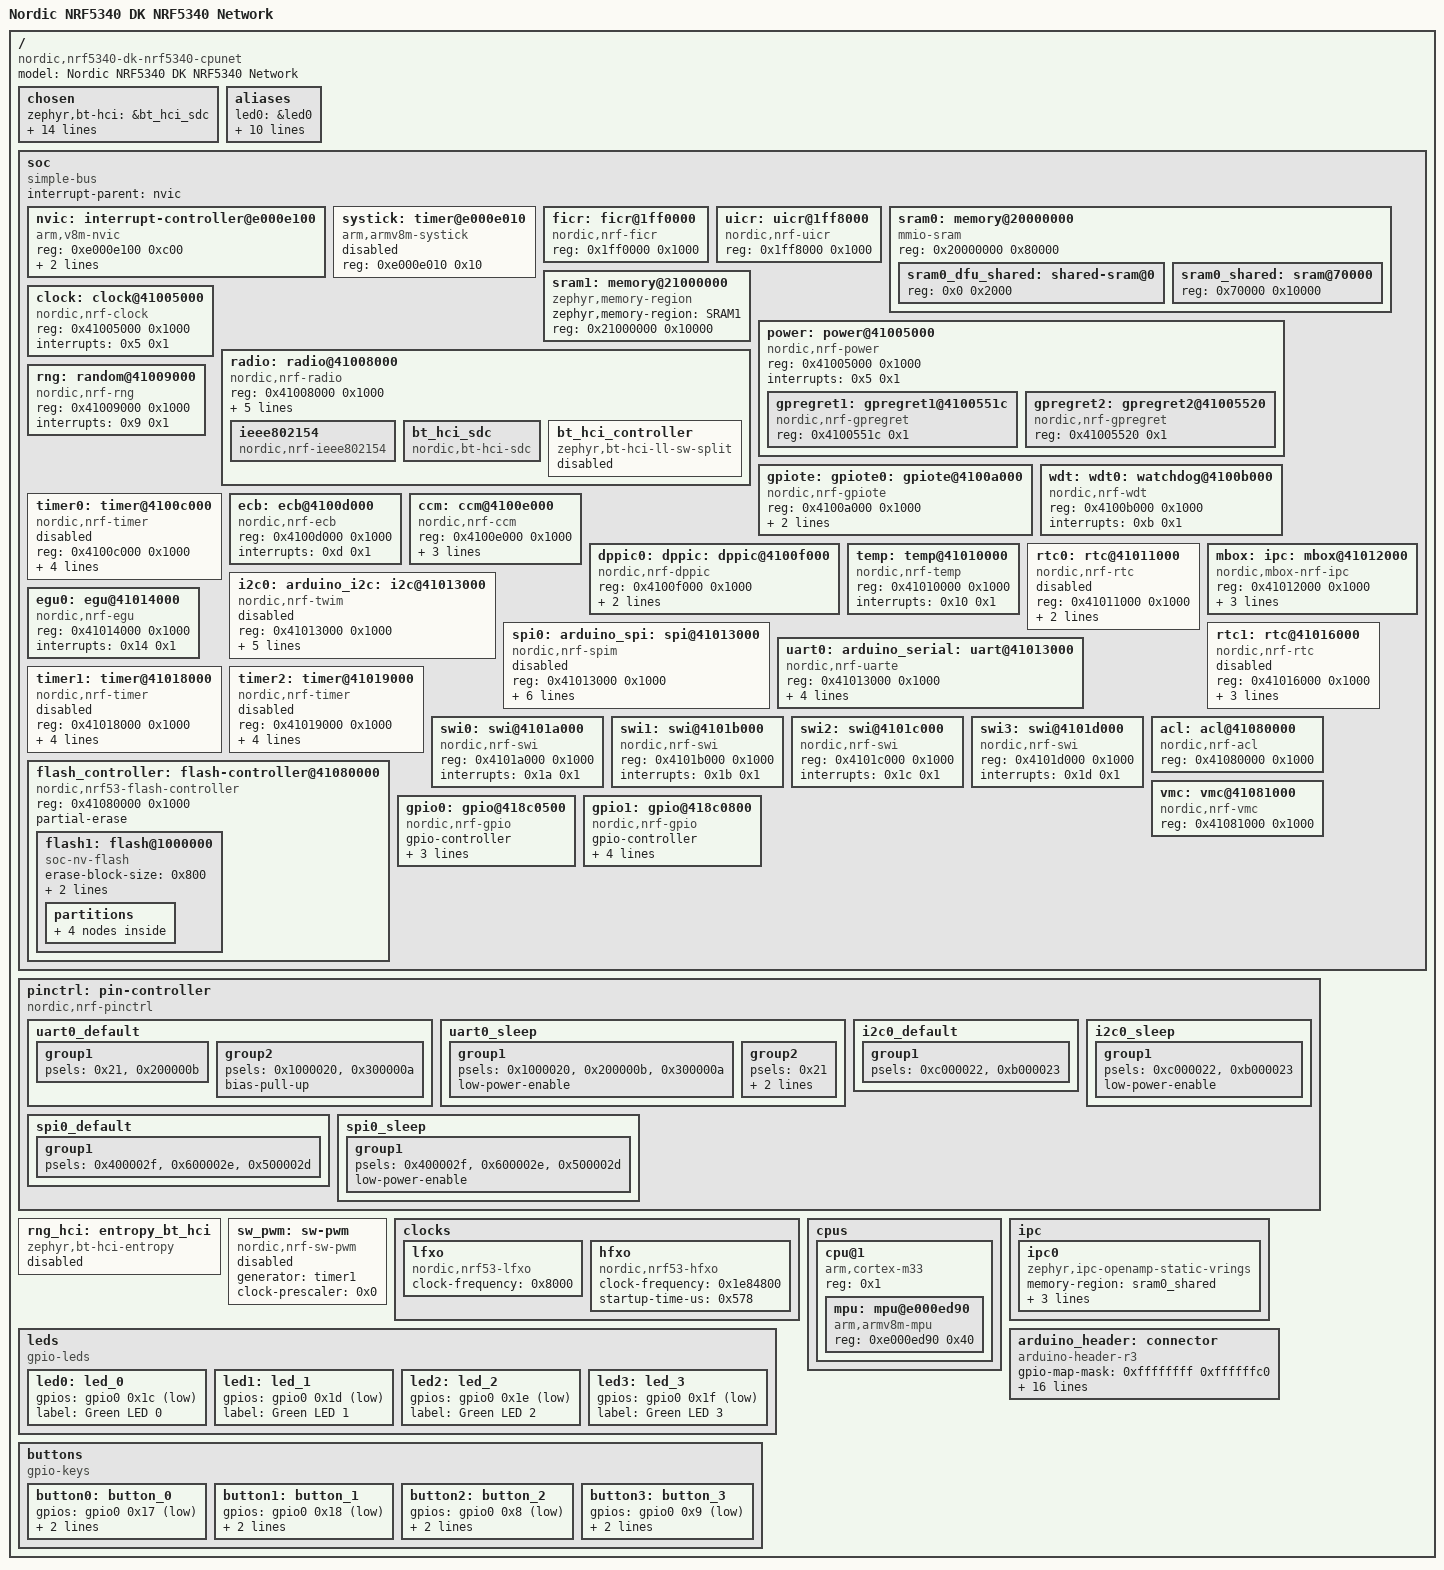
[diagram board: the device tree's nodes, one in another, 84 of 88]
/dts-v1/;

/* node '/' defined in zephyr/dts/common/skeleton.dtsi:9 */
/ {
	#address-cells = < 0x1 >;                        /* in zephyr/dts/common/skeleton.dtsi:10 */
	#size-cells = < 0x1 >;                           /* in zephyr/dts/common/skeleton.dtsi:11 */
	model = "Nordic NRF5340 DK NRF5340 Network";     /* in zephyr/boards/nordic/nrf5340dk/nrf5340dk_nrf5340_cpunet.dts:14 */
	compatible = "nordic,nrf5340-dk-nrf5340-cpunet"; /* in zephyr/boards/nordic/nrf5340dk/nrf5340dk_nrf5340_cpunet.dts:15 */

	/* node '/chosen' defined in zephyr/dts/common/skeleton.dtsi:13 */
	chosen {
		zephyr,bt-hci = &bt_hci_sdc;                 /* in zephyr/dts/arm/nordic/nrf5340_cpunet.dtsi:13 */
		zephyr,entropy = &rng;                       /* in zephyr/dts/arm/nordic/nrf5340_cpunet.dtsi:14 */
		zephyr,flash-controller = &flash_controller; /* in zephyr/dts/arm/nordic/nrf5340_cpunet.dtsi:15 */
		zephyr,console = &uart0;                     /* in zephyr/boards/nordic/nrf5340dk/nrf5340dk_nrf5340_cpunet.dts:18 */
		zephyr,shell-uart = &uart0;                  /* in zephyr/boards/nordic/nrf5340dk/nrf5340dk_nrf5340_cpunet.dts:19 */
		zephyr,uart-mcumgr = &uart0;                 /* in zephyr/boards/nordic/nrf5340dk/nrf5340dk_nrf5340_cpunet.dts:20 */
		zephyr,bt-mon-uart = &uart0;                 /* in zephyr/boards/nordic/nrf5340dk/nrf5340dk_nrf5340_cpunet.dts:21 */
		zephyr,bt-c2h-uart = &uart0;                 /* in zephyr/boards/nordic/nrf5340dk/nrf5340dk_nrf5340_cpunet.dts:22 */
		zephyr,bt-hci-ipc = &ipc0;                   /* in zephyr/boards/nordic/nrf5340dk/nrf5340dk_nrf5340_cpunet.dts:23 */
		nordic,802154-spinel-ipc = &ipc0;            /* in zephyr/boards/nordic/nrf5340dk/nrf5340dk_nrf5340_cpunet.dts:24 */
		zephyr,sram = &sram1;                        /* in zephyr/boards/nordic/nrf5340dk/nrf5340dk_nrf5340_cpunet.dts:25 */
		zephyr,flash = &flash1;                      /* in zephyr/boards/nordic/nrf5340dk/nrf5340dk_nrf5340_cpunet.dts:26 */
		zephyr,code-partition = &slot0_partition;    /* in zephyr/boards/nordic/nrf5340dk/nrf5340dk_nrf5340_cpunet.dts:27 */
		zephyr,ieee802154 = &ieee802154;             /* in zephyr/boards/nordic/nrf5340dk/nrf5340dk_nrf5340_cpunet.dts:28 */
		zephyr,ipc_shm = &sram0_shared;              /* in zephyr/dts/vendor/nordic/nrf5340_shared_sram_partition.dtsi:22 */
	};

	/* node '/aliases' defined in zephyr/dts/common/skeleton.dtsi:15 */
	aliases {
		led0 = &led0;               /* in zephyr/boards/nordic/nrf5340dk/nrf5340dk_common.dtsi:93 */
		led1 = &led1;               /* in zephyr/boards/nordic/nrf5340dk/nrf5340dk_common.dtsi:94 */
		led2 = &led2;               /* in zephyr/boards/nordic/nrf5340dk/nrf5340dk_common.dtsi:95 */
		led3 = &led3;               /* in zephyr/boards/nordic/nrf5340dk/nrf5340dk_common.dtsi:96 */
		sw0 = &button0;             /* in zephyr/boards/nordic/nrf5340dk/nrf5340dk_common.dtsi:97 */
		sw1 = &button1;             /* in zephyr/boards/nordic/nrf5340dk/nrf5340dk_common.dtsi:98 */
		sw2 = &button2;             /* in zephyr/boards/nordic/nrf5340dk/nrf5340dk_common.dtsi:99 */
		sw3 = &button3;             /* in zephyr/boards/nordic/nrf5340dk/nrf5340dk_common.dtsi:100 */
		mcuboot-button0 = &button0; /* in zephyr/boards/nordic/nrf5340dk/nrf5340dk_common.dtsi:101 */
		mcuboot-led0 = &led0;       /* in zephyr/boards/nordic/nrf5340dk/nrf5340dk_common.dtsi:102 */
		watchdog0 = &wdt0;          /* in zephyr/boards/nordic/nrf5340dk/nrf5340dk_nrf5340_cpunet.dts:33 */
	};

	/* node '/soc' defined in zephyr/dts/arm/armv8-m.dtsi:6 */
	soc {
		#address-cells = < 0x1 >;     /* in zephyr/dts/arm/armv8-m.dtsi:7 */
		#size-cells = < 0x1 >;        /* in zephyr/dts/arm/armv8-m.dtsi:8 */
		interrupt-parent = < &nvic >; /* in zephyr/dts/arm/armv8-m.dtsi:10 */
		ranges;                       /* in zephyr/dts/arm/armv8-m.dtsi:11 */
		compatible = "simple-bus";    /* in zephyr/dts/arm/nordic/nrf5340_cpunet.dtsi:37 */

		/* node '/soc/interrupt-controller@e000e100' defined in zephyr/dts/arm/armv8-m.dtsi:13 */
		nvic: interrupt-controller@e000e100 {
			#address-cells = < 0x1 >;            /* in zephyr/dts/arm/armv8-m.dtsi:14 */
			compatible = "arm,v8m-nvic";         /* in zephyr/dts/arm/armv8-m.dtsi:15 */
			reg = < 0xe000e100 0xc00 >;          /* in zephyr/dts/arm/armv8-m.dtsi:16 */
			interrupt-controller;                /* in zephyr/dts/arm/armv8-m.dtsi:17 */
			#interrupt-cells = < 0x2 >;          /* in zephyr/dts/arm/armv8-m.dtsi:18 */
			arm,num-irq-priority-bits = < 0x3 >; /* in zephyr/dts/arm/nordic/nrf5340_cpunet.dtsi:379 */
			phandle = < 0x1 >;                   /* in zephyr/dts/arm/armv8-m.dtsi:10 */
		};

		/* node '/soc/timer@e000e010' defined in zephyr/dts/arm/armv8-m.dtsi:21 */
		systick: timer@e000e010 {
			compatible = "arm,armv8m-systick"; /* in zephyr/dts/arm/armv8-m.dtsi:22 */
			reg = < 0xe000e010 0x10 >;         /* in zephyr/dts/arm/armv8-m.dtsi:23 */
			status = "disabled";               /* in zephyr/dts/arm/nordic/nrf5340_cpunet.dtsi:384 */
		};

		/* node '/soc/ficr@1ff0000' defined in zephyr/dts/arm/nordic/nrf5340_cpunet.dtsi:39 */
		ficr: ficr@1ff0000 {
			compatible = "nordic,nrf-ficr"; /* in zephyr/dts/arm/nordic/nrf5340_cpunet.dtsi:40 */
			reg = < 0x1ff0000 0x1000 >;     /* in zephyr/dts/arm/nordic/nrf5340_cpunet.dtsi:41 */
			#nordic,ficr-cells = < 0x1 >;   /* in zephyr/dts/arm/nordic/nrf5340_cpunet.dtsi:42 */
			status = "okay";                /* in zephyr/dts/arm/nordic/nrf5340_cpunet.dtsi:43 */
		};

		/* node '/soc/uicr@1ff8000' defined in zephyr/dts/arm/nordic/nrf5340_cpunet.dtsi:46 */
		uicr: uicr@1ff8000 {
			compatible = "nordic,nrf-uicr";    /* in zephyr/dts/arm/nordic/nrf5340_cpunet.dtsi:47 */
			reg = < 0x1ff8000 0x1000 >;        /* in zephyr/dts/arm/nordic/nrf5340_cpunet.dtsi:48 */
			ranges = < 0x0 0x1ff8000 0x1000 >; /* in zephyr/dts/arm/nordic/nrf5340_cpunet.dtsi:49 */
			status = "okay";                   /* in zephyr/dts/arm/nordic/nrf5340_cpunet.dtsi:50 */
			#address-cells = < 0x1 >;          /* in zephyr/dts/arm/nordic/nrf5340_cpunet.dtsi:51 */
			#size-cells = < 0x1 >;             /* in zephyr/dts/arm/nordic/nrf5340_cpunet.dtsi:52 */
		};

		/* node '/soc/memory@20000000' defined in zephyr/dts/arm/nordic/nrf5340_cpunet.dtsi:55 */
		sram0: memory@20000000 {
			compatible = "mmio-sram";            /* in zephyr/dts/arm/nordic/nrf5340_cpunet.dtsi:56 */
			#address-cells = < 0x1 >;            /* in zephyr/dts/arm/nordic/nrf5340_cpunet.dtsi:57 */
			#size-cells = < 0x1 >;               /* in zephyr/dts/arm/nordic/nrf5340_cpunet.dtsi:58 */
			reg = < 0x20000000 0x80000 >;        /* in zephyr/dts/arm/nordic/nrf5340_cpunet_qkaa.dtsi:11 */
			ranges = < 0x0 0x20000000 0x80000 >; /* in zephyr/dts/arm/nordic/nrf5340_cpunet_qkaa.dtsi:12 */

			/* node '/soc/memory@20000000/shared-sram@0' defined in zephyr/dts/vendor/nordic/nrf5340_shared_sram_partition.dtsi:27 */
			sram0_dfu_shared: shared-sram@0 {
				reg = < 0x0 0x2000 >; /* in zephyr/dts/vendor/nordic/nrf5340_shared_sram_partition.dtsi:28 */
			};

			/* node '/soc/memory@20000000/sram@70000' defined in zephyr/dts/vendor/nordic/nrf5340_shared_sram_partition.dtsi:31 */
			sram0_shared: sram@70000 {
				reg = < 0x70000 0x10000 >; /* in zephyr/dts/vendor/nordic/nrf5340_shared_sram_partition.dtsi:33 */
				phandle = < 0xb >;         /* in zephyr/dts/arm/nordic/nrf5340_cpunet.dtsi:369 */
			};
		};

		/* node '/soc/memory@21000000' defined in zephyr/dts/arm/nordic/nrf5340_cpunet.dtsi:61 */
		sram1: memory@21000000 {
			compatible = "zephyr,memory-region",
			             "mmio-sram";            /* in zephyr/dts/arm/nordic/nrf5340_cpunet.dtsi:62 */
			zephyr,memory-region = "SRAM1";      /* in zephyr/dts/arm/nordic/nrf5340_cpunet.dtsi:63 */
			#address-cells = < 0x1 >;            /* in zephyr/dts/arm/nordic/nrf5340_cpunet.dtsi:64 */
			#size-cells = < 0x1 >;               /* in zephyr/dts/arm/nordic/nrf5340_cpunet.dtsi:65 */
			reg = < 0x21000000 0x10000 >;        /* in zephyr/dts/arm/nordic/nrf5340_cpunet_qkaa.dtsi:16 */
			ranges = < 0x0 0x21000000 0x10000 >; /* in zephyr/dts/arm/nordic/nrf5340_cpunet_qkaa.dtsi:17 */
		};

		/* node '/soc/clock@41005000' defined in zephyr/dts/arm/nordic/nrf5340_cpunet.dtsi:68 */
		clock: clock@41005000 {
			compatible = "nordic,nrf-clock"; /* in zephyr/dts/arm/nordic/nrf5340_cpunet.dtsi:69 */
			reg = < 0x41005000 0x1000 >;     /* in zephyr/dts/arm/nordic/nrf5340_cpunet.dtsi:70 */
			interrupts = < 0x5 0x1 >;        /* in zephyr/dts/arm/nordic/nrf5340_cpunet.dtsi:71 */
			status = "okay";                 /* in zephyr/dts/arm/nordic/nrf5340_cpunet.dtsi:72 */
		};

		/* node '/soc/power@41005000' defined in zephyr/dts/arm/nordic/nrf5340_cpunet.dtsi:75 */
		power: power@41005000 {
			compatible = "nordic,nrf-power"; /* in zephyr/dts/arm/nordic/nrf5340_cpunet.dtsi:76 */
			reg = < 0x41005000 0x1000 >;     /* in zephyr/dts/arm/nordic/nrf5340_cpunet.dtsi:77 */
			interrupts = < 0x5 0x1 >;        /* in zephyr/dts/arm/nordic/nrf5340_cpunet.dtsi:78 */
			status = "okay";                 /* in zephyr/dts/arm/nordic/nrf5340_cpunet.dtsi:79 */
			#address-cells = < 0x1 >;        /* in zephyr/dts/arm/nordic/nrf5340_cpunet.dtsi:80 */
			#size-cells = < 0x1 >;           /* in zephyr/dts/arm/nordic/nrf5340_cpunet.dtsi:81 */

			/* node '/soc/power@41005000/gpregret1@4100551c' defined in zephyr/dts/arm/nordic/nrf5340_cpunet.dtsi:83 */
			gpregret1: gpregret1@4100551c {
				#address-cells = < 0x1 >;           /* in zephyr/dts/arm/nordic/nrf5340_cpunet.dtsi:84 */
				#size-cells = < 0x1 >;              /* in zephyr/dts/arm/nordic/nrf5340_cpunet.dtsi:85 */
				compatible = "nordic,nrf-gpregret"; /* in zephyr/dts/arm/nordic/nrf5340_cpunet.dtsi:86 */
				reg = < 0x4100551c 0x1 >;           /* in zephyr/dts/arm/nordic/nrf5340_cpunet.dtsi:87 */
				status = "okay";                    /* in zephyr/dts/arm/nordic/nrf5340_cpunet.dtsi:88 */
			};

			/* node '/soc/power@41005000/gpregret2@41005520' defined in zephyr/dts/arm/nordic/nrf5340_cpunet.dtsi:91 */
			gpregret2: gpregret2@41005520 {
				#address-cells = < 0x1 >;           /* in zephyr/dts/arm/nordic/nrf5340_cpunet.dtsi:92 */
				#size-cells = < 0x1 >;              /* in zephyr/dts/arm/nordic/nrf5340_cpunet.dtsi:93 */
				compatible = "nordic,nrf-gpregret"; /* in zephyr/dts/arm/nordic/nrf5340_cpunet.dtsi:94 */
				reg = < 0x41005520 0x1 >;           /* in zephyr/dts/arm/nordic/nrf5340_cpunet.dtsi:95 */
				status = "okay";                    /* in zephyr/dts/arm/nordic/nrf5340_cpunet.dtsi:96 */
			};
		};

		/* node '/soc/radio@41008000' defined in zephyr/dts/arm/nordic/nrf5340_cpunet.dtsi:100 */
		radio: radio@41008000 {
			compatible = "nordic,nrf-radio"; /* in zephyr/dts/arm/nordic/nrf5340_cpunet.dtsi:101 */
			reg = < 0x41008000 0x1000 >;     /* in zephyr/dts/arm/nordic/nrf5340_cpunet.dtsi:102 */
			interrupts = < 0x8 0x1 >;        /* in zephyr/dts/arm/nordic/nrf5340_cpunet.dtsi:103 */
			status = "okay";                 /* in zephyr/dts/arm/nordic/nrf5340_cpunet.dtsi:104 */
			dfe-supported;                   /* in zephyr/dts/arm/nordic/nrf5340_cpunet.dtsi:105 */
			ieee802154-supported;            /* in zephyr/dts/arm/nordic/nrf5340_cpunet.dtsi:106 */
			ble-2mbps-supported;             /* in zephyr/dts/arm/nordic/nrf5340_cpunet.dtsi:107 */
			ble-coded-phy-supported;         /* in zephyr/dts/arm/nordic/nrf5340_cpunet.dtsi:108 */

			/* node '/soc/radio@41008000/ieee802154' defined in zephyr/dts/arm/nordic/nrf5340_cpunet.dtsi:110 */
			ieee802154: ieee802154 {
				compatible = "nordic,nrf-ieee802154"; /* in zephyr/dts/arm/nordic/nrf5340_cpunet.dtsi:111 */
				status = "okay";                      /* in zephyr/boards/nordic/nrf5340dk/nrf5340dk_nrf5340_cpunet.dts:111 */
			};

			/* node '/soc/radio@41008000/bt_hci_sdc' defined in zephyr/dts/arm/nordic/nrf5340_cpunet.dtsi:115 */
			bt_hci_sdc: bt_hci_sdc {
				compatible = "nordic,bt-hci-sdc"; /* in zephyr/dts/arm/nordic/nrf5340_cpunet.dtsi:116 */
				status = "okay";                  /* in zephyr/dts/arm/nordic/nrf5340_cpunet.dtsi:117 */
			};

			/* node '/soc/radio@41008000/bt_hci_controller' defined in zephyr/dts/arm/nordic/nrf5340_cpunet.dtsi:119 */
			bt_hci_controller: bt_hci_controller {
				compatible = "zephyr,bt-hci-ll-sw-split"; /* in zephyr/dts/arm/nordic/nrf5340_cpunet.dtsi:120 */
				status = "disabled";                      /* in zephyr/dts/arm/nordic/nrf5340_cpunet.dtsi:121 */
			};
		};

		/* node '/soc/random@41009000' defined in zephyr/dts/arm/nordic/nrf5340_cpunet.dtsi:125 */
		rng: random@41009000 {
			compatible = "nordic,nrf-rng"; /* in zephyr/dts/arm/nordic/nrf5340_cpunet.dtsi:126 */
			reg = < 0x41009000 0x1000 >;   /* in zephyr/dts/arm/nordic/nrf5340_cpunet.dtsi:127 */
			interrupts = < 0x9 0x1 >;      /* in zephyr/dts/arm/nordic/nrf5340_cpunet.dtsi:128 */
			status = "okay";               /* in zephyr/dts/arm/nordic/nrf5340_cpunet.dtsi:129 */
		};

		/* node '/soc/gpiote@4100a000' defined in zephyr/dts/arm/nordic/nrf5340_cpunet.dtsi:132 */
		gpiote: gpiote0: gpiote@4100a000 {
			compatible = "nordic,nrf-gpiote"; /* in zephyr/dts/arm/nordic/nrf5340_cpunet.dtsi:133 */
			reg = < 0x4100a000 0x1000 >;      /* in zephyr/dts/arm/nordic/nrf5340_cpunet.dtsi:134 */
			interrupts = < 0xa 0x5 >;         /* in zephyr/dts/arm/nordic/nrf5340_cpunet.dtsi:135 */
			instance = < 0x0 >;               /* in zephyr/dts/arm/nordic/nrf5340_cpunet.dtsi:137 */
			status = "okay";                  /* in zephyr/boards/nordic/nrf5340dk/nrf5340dk_nrf5340_cpunet.dts:38 */
			phandle = < 0x9 >;                /* in zephyr/dts/arm/nordic/nrf5340_cpunet.dtsi:350 */
		};

		/* node '/soc/watchdog@4100b000' defined in zephyr/dts/arm/nordic/nrf5340_cpunet.dtsi:140 */
		wdt: wdt0: watchdog@4100b000 {
			compatible = "nordic,nrf-wdt"; /* in zephyr/dts/arm/nordic/nrf5340_cpunet.dtsi:141 */
			reg = < 0x4100b000 0x1000 >;   /* in zephyr/dts/arm/nordic/nrf5340_cpunet.dtsi:142 */
			interrupts = < 0xb 0x1 >;      /* in zephyr/dts/arm/nordic/nrf5340_cpunet.dtsi:143 */
			status = "okay";               /* in zephyr/dts/arm/nordic/nrf5340_cpunet.dtsi:144 */
		};

		/* node '/soc/timer@4100c000' defined in zephyr/dts/arm/nordic/nrf5340_cpunet.dtsi:147 */
		timer0: timer@4100c000 {
			compatible = "nordic,nrf-timer"; /* in zephyr/dts/arm/nordic/nrf5340_cpunet.dtsi:148 */
			status = "disabled";             /* in zephyr/dts/arm/nordic/nrf5340_cpunet.dtsi:149 */
			reg = < 0x4100c000 0x1000 >;     /* in zephyr/dts/arm/nordic/nrf5340_cpunet.dtsi:150 */
			cc-num = < 0x8 >;                /* in zephyr/dts/arm/nordic/nrf5340_cpunet.dtsi:151 */
			max-bit-width = < 0x20 >;        /* in zephyr/dts/arm/nordic/nrf5340_cpunet.dtsi:152 */
			interrupts = < 0xc 0x1 >;        /* in zephyr/dts/arm/nordic/nrf5340_cpunet.dtsi:153 */
			prescaler = < 0x0 >;             /* in zephyr/dts/arm/nordic/nrf5340_cpunet.dtsi:154 */
		};

		/* node '/soc/ecb@4100d000' defined in zephyr/dts/arm/nordic/nrf5340_cpunet.dtsi:157 */
		ecb: ecb@4100d000 {
			compatible = "nordic,nrf-ecb"; /* in zephyr/dts/arm/nordic/nrf5340_cpunet.dtsi:158 */
			reg = < 0x4100d000 0x1000 >;   /* in zephyr/dts/arm/nordic/nrf5340_cpunet.dtsi:159 */
			interrupts = < 0xd 0x1 >;      /* in zephyr/dts/arm/nordic/nrf5340_cpunet.dtsi:160 */
			status = "okay";               /* in zephyr/dts/arm/nordic/nrf5340_cpunet.dtsi:161 */
		};

		/* node '/soc/ccm@4100e000' defined in zephyr/dts/arm/nordic/nrf5340_cpunet.dtsi:164 */
		ccm: ccm@4100e000 {
			compatible = "nordic,nrf-ccm"; /* in zephyr/dts/arm/nordic/nrf5340_cpunet.dtsi:165 */
			reg = < 0x4100e000 0x1000 >;   /* in zephyr/dts/arm/nordic/nrf5340_cpunet.dtsi:166 */
			interrupts = < 0xe 0x1 >;      /* in zephyr/dts/arm/nordic/nrf5340_cpunet.dtsi:167 */
			length-field-length-8-bits;    /* in zephyr/dts/arm/nordic/nrf5340_cpunet.dtsi:168 */
			headermask-supported;          /* in zephyr/dts/arm/nordic/nrf5340_cpunet.dtsi:169 */
			status = "okay";               /* in zephyr/dts/arm/nordic/nrf5340_cpunet.dtsi:170 */
		};

		/* node '/soc/dppic@4100f000' defined in zephyr/dts/arm/nordic/nrf5340_cpunet.dtsi:173 */
		dppic0: dppic: dppic@4100f000 {
			compatible = "nordic,nrf-dppic"; /* in zephyr/dts/arm/nordic/nrf5340_cpunet.dtsi:174 */
			reg = < 0x4100f000 0x1000 >;     /* in zephyr/dts/arm/nordic/nrf5340_cpunet.dtsi:175 */
			status = "okay";                 /* in zephyr/dts/arm/nordic/nrf5340_cpunet.dtsi:176 */
			channels = < 0x10 >;             /* in zephyr/dts/arm/nordic/nrf5340_cpunet.dtsi:177 */
			groups = < 0x6 >;                /* in zephyr/dts/arm/nordic/nrf5340_cpunet.dtsi:178 */
		};

		/* node '/soc/temp@41010000' defined in zephyr/dts/arm/nordic/nrf5340_cpunet.dtsi:181 */
		temp: temp@41010000 {
			compatible = "nordic,nrf-temp"; /* in zephyr/dts/arm/nordic/nrf5340_cpunet.dtsi:182 */
			reg = < 0x41010000 0x1000 >;    /* in zephyr/dts/arm/nordic/nrf5340_cpunet.dtsi:183 */
			interrupts = < 0x10 0x1 >;      /* in zephyr/dts/arm/nordic/nrf5340_cpunet.dtsi:184 */
			status = "okay";                /* in zephyr/dts/arm/nordic/nrf5340_cpunet.dtsi:185 */
		};

		/* node '/soc/rtc@41011000' defined in zephyr/dts/arm/nordic/nrf5340_cpunet.dtsi:188 */
		rtc0: rtc@41011000 {
			compatible = "nordic,nrf-rtc"; /* in zephyr/dts/arm/nordic/nrf5340_cpunet.dtsi:189 */
			reg = < 0x41011000 0x1000 >;   /* in zephyr/dts/arm/nordic/nrf5340_cpunet.dtsi:190 */
			cc-num = < 0x4 >;              /* in zephyr/dts/arm/nordic/nrf5340_cpunet.dtsi:191 */
			interrupts = < 0x11 0x1 >;     /* in zephyr/dts/arm/nordic/nrf5340_cpunet.dtsi:192 */
			status = "disabled";           /* in zephyr/dts/arm/nordic/nrf5340_cpunet.dtsi:193 */
		};

		/* node '/soc/mbox@41012000' defined in zephyr/dts/arm/nordic/nrf5340_cpunet.dtsi:196 */
		mbox: ipc: mbox@41012000 {
			compatible = "nordic,mbox-nrf-ipc",
			             "nordic,nrf-ipc";      /* in zephyr/dts/arm/nordic/nrf5340_cpunet.dtsi:197 */
			reg = < 0x41012000 0x1000 >;        /* in zephyr/dts/arm/nordic/nrf5340_cpunet.dtsi:198 */
			tx-mask = < 0xffff >;               /* in zephyr/dts/arm/nordic/nrf5340_cpunet.dtsi:199 */
			rx-mask = < 0xffff >;               /* in zephyr/dts/arm/nordic/nrf5340_cpunet.dtsi:200 */
			interrupts = < 0x12 0x1 >;          /* in zephyr/dts/arm/nordic/nrf5340_cpunet.dtsi:201 */
			#mbox-cells = < 0x1 >;              /* in zephyr/dts/arm/nordic/nrf5340_cpunet.dtsi:202 */
			status = "okay";                    /* in zephyr/dts/arm/nordic/nrf5340_cpunet.dtsi:203 */
			phandle = < 0xc >;                  /* in zephyr/dts/arm/nordic/nrf5340_cpunet.dtsi:370 */
		};

		/* node '/soc/i2c@41013000' defined in zephyr/dts/arm/nordic/nrf5340_cpunet.dtsi:206 */
		i2c0: arduino_i2c: i2c@41013000 {
			#address-cells = < 0x1 >;       /* in zephyr/dts/arm/nordic/nrf5340_cpunet.dtsi:214 */
			#size-cells = < 0x0 >;          /* in zephyr/dts/arm/nordic/nrf5340_cpunet.dtsi:215 */
			reg = < 0x41013000 0x1000 >;    /* in zephyr/dts/arm/nordic/nrf5340_cpunet.dtsi:216 */
			interrupts = < 0x13 0x1 >;      /* in zephyr/dts/arm/nordic/nrf5340_cpunet.dtsi:217 */
			easydma-maxcnt-bits = < 0x10 >; /* in zephyr/dts/arm/nordic/nrf5340_cpunet.dtsi:218 */
			status = "disabled";            /* in zephyr/dts/arm/nordic/nrf5340_cpunet.dtsi:219 */
			zephyr,pm-device-runtime-auto;  /* in zephyr/dts/arm/nordic/nrf5340_cpunet.dtsi:220 */
			compatible = "nordic,nrf-twim"; /* in zephyr/boards/nordic/nrf5340dk/nrf5340dk_nrf5340_cpunet.dts:60 */
			pinctrl-0 = < &i2c0_default >;  /* in zephyr/boards/nordic/nrf5340dk/nrf5340dk_nrf5340_cpunet.dts:63 */
			pinctrl-1 = < &i2c0_sleep >;    /* in zephyr/boards/nordic/nrf5340dk/nrf5340dk_nrf5340_cpunet.dts:64 */
			pinctrl-names = "default",
			                "sleep";        /* in zephyr/boards/nordic/nrf5340dk/nrf5340dk_nrf5340_cpunet.dts:65 */
		};

		/* node '/soc/spi@41013000' defined in zephyr/dts/arm/nordic/nrf5340_cpunet.dtsi:223 */
		spi0: arduino_spi: spi@41013000 {
			#address-cells = < 0x1 >;                /* in zephyr/dts/arm/nordic/nrf5340_cpunet.dtsi:231 */
			#size-cells = < 0x0 >;                   /* in zephyr/dts/arm/nordic/nrf5340_cpunet.dtsi:232 */
			reg = < 0x41013000 0x1000 >;             /* in zephyr/dts/arm/nordic/nrf5340_cpunet.dtsi:233 */
			interrupts = < 0x13 0x1 >;               /* in zephyr/dts/arm/nordic/nrf5340_cpunet.dtsi:234 */
			max-frequency = < 0x7a1200 >;            /* in zephyr/dts/arm/nordic/nrf5340_cpunet.dtsi:235 */
			easydma-maxcnt-bits = < 0x10 >;          /* in zephyr/dts/arm/nordic/nrf5340_cpunet.dtsi:236 */
			status = "disabled";                     /* in zephyr/dts/arm/nordic/nrf5340_cpunet.dtsi:237 */
			compatible = "nordic,nrf-spim";          /* in zephyr/boards/nordic/nrf5340dk/nrf5340dk_nrf5340_cpunet.dts:69 */
			cs-gpios = < &arduino_header 0x10 0x1 >; /* in zephyr/boards/nordic/nrf5340dk/nrf5340dk_nrf5340_cpunet.dts:72 */
			pinctrl-0 = < &spi0_default >;           /* in zephyr/boards/nordic/nrf5340dk/nrf5340dk_nrf5340_cpunet.dts:73 */
			pinctrl-1 = < &spi0_sleep >;             /* in zephyr/boards/nordic/nrf5340dk/nrf5340dk_nrf5340_cpunet.dts:74 */
			pinctrl-names = "default",
			                "sleep";                 /* in zephyr/boards/nordic/nrf5340dk/nrf5340dk_nrf5340_cpunet.dts:75 */
		};

		/* node '/soc/uart@41013000' defined in zephyr/dts/arm/nordic/nrf5340_cpunet.dtsi:240 */
		uart0: arduino_serial: uart@41013000 {
			compatible = "nordic,nrf-uarte"; /* in zephyr/dts/arm/nordic/nrf5340_cpunet.dtsi:241 */
			reg = < 0x41013000 0x1000 >;     /* in zephyr/dts/arm/nordic/nrf5340_cpunet.dtsi:242 */
			interrupts = < 0x13 0x1 >;       /* in zephyr/dts/arm/nordic/nrf5340_cpunet.dtsi:243 */
			status = "okay";                 /* in zephyr/boards/nordic/nrf5340dk/nrf5340dk_nrf5340_cpunet.dts:50 */
			current-speed = < 0x1c200 >;     /* in zephyr/boards/nordic/nrf5340dk/nrf5340dk_nrf5340_cpunet.dts:51 */
			pinctrl-0 = < &uart0_default >;  /* in zephyr/boards/nordic/nrf5340dk/nrf5340dk_nrf5340_cpunet.dts:52 */
			pinctrl-1 = < &uart0_sleep >;    /* in zephyr/boards/nordic/nrf5340dk/nrf5340dk_nrf5340_cpunet.dts:53 */
			pinctrl-names = "default",
			                "sleep";         /* in zephyr/boards/nordic/nrf5340dk/nrf5340dk_nrf5340_cpunet.dts:54 */
		};

		/* node '/soc/egu@41014000' defined in zephyr/dts/arm/nordic/nrf5340_cpunet.dtsi:247 */
		egu0: egu@41014000 {
			compatible = "nordic,nrf-egu"; /* in zephyr/dts/arm/nordic/nrf5340_cpunet.dtsi:248 */
			reg = < 0x41014000 0x1000 >;   /* in zephyr/dts/arm/nordic/nrf5340_cpunet.dtsi:249 */
			interrupts = < 0x14 0x1 >;     /* in zephyr/dts/arm/nordic/nrf5340_cpunet.dtsi:250 */
			status = "okay";               /* in zephyr/dts/arm/nordic/nrf5340_cpunet.dtsi:251 */
		};

		/* node '/soc/rtc@41016000' defined in zephyr/dts/arm/nordic/nrf5340_cpunet.dtsi:254 */
		rtc1: rtc@41016000 {
			compatible = "nordic,nrf-rtc"; /* in zephyr/dts/arm/nordic/nrf5340_cpunet.dtsi:255 */
			reg = < 0x41016000 0x1000 >;   /* in zephyr/dts/arm/nordic/nrf5340_cpunet.dtsi:256 */
			cc-num = < 0x4 >;              /* in zephyr/dts/arm/nordic/nrf5340_cpunet.dtsi:257 */
			interrupts = < 0x16 0x1 >;     /* in zephyr/dts/arm/nordic/nrf5340_cpunet.dtsi:258 */
			clock-frequency = < 0x8000 >;  /* in zephyr/dts/arm/nordic/nrf5340_cpunet.dtsi:259 */
			status = "disabled";           /* in zephyr/dts/arm/nordic/nrf5340_cpunet.dtsi:260 */
		};

		/* node '/soc/timer@41018000' defined in zephyr/dts/arm/nordic/nrf5340_cpunet.dtsi:263 */
		timer1: timer@41018000 {
			compatible = "nordic,nrf-timer"; /* in zephyr/dts/arm/nordic/nrf5340_cpunet.dtsi:264 */
			status = "disabled";             /* in zephyr/dts/arm/nordic/nrf5340_cpunet.dtsi:265 */
			reg = < 0x41018000 0x1000 >;     /* in zephyr/dts/arm/nordic/nrf5340_cpunet.dtsi:266 */
			cc-num = < 0x8 >;                /* in zephyr/dts/arm/nordic/nrf5340_cpunet.dtsi:267 */
			max-bit-width = < 0x20 >;        /* in zephyr/dts/arm/nordic/nrf5340_cpunet.dtsi:268 */
			interrupts = < 0x18 0x1 >;       /* in zephyr/dts/arm/nordic/nrf5340_cpunet.dtsi:269 */
			prescaler = < 0x0 >;             /* in zephyr/dts/arm/nordic/nrf5340_cpunet.dtsi:270 */
			phandle = < 0xa >;               /* in zephyr/dts/vendor/nordic/nrf_common.dtsi:42 */
		};

		/* node '/soc/timer@41019000' defined in zephyr/dts/arm/nordic/nrf5340_cpunet.dtsi:273 */
		timer2: timer@41019000 {
			compatible = "nordic,nrf-timer"; /* in zephyr/dts/arm/nordic/nrf5340_cpunet.dtsi:274 */
			status = "disabled";             /* in zephyr/dts/arm/nordic/nrf5340_cpunet.dtsi:275 */
			reg = < 0x41019000 0x1000 >;     /* in zephyr/dts/arm/nordic/nrf5340_cpunet.dtsi:276 */
			cc-num = < 0x8 >;                /* in zephyr/dts/arm/nordic/nrf5340_cpunet.dtsi:277 */
			max-bit-width = < 0x20 >;        /* in zephyr/dts/arm/nordic/nrf5340_cpunet.dtsi:278 */
			interrupts = < 0x19 0x1 >;       /* in zephyr/dts/arm/nordic/nrf5340_cpunet.dtsi:279 */
			prescaler = < 0x0 >;             /* in zephyr/dts/arm/nordic/nrf5340_cpunet.dtsi:280 */
		};

		/* node '/soc/swi@4101a000' defined in zephyr/dts/arm/nordic/nrf5340_cpunet.dtsi:283 */
		swi0: swi@4101a000 {
			compatible = "nordic,nrf-swi"; /* in zephyr/dts/arm/nordic/nrf5340_cpunet.dtsi:284 */
			reg = < 0x4101a000 0x1000 >;   /* in zephyr/dts/arm/nordic/nrf5340_cpunet.dtsi:285 */
			interrupts = < 0x1a 0x1 >;     /* in zephyr/dts/arm/nordic/nrf5340_cpunet.dtsi:286 */
			status = "okay";               /* in zephyr/dts/arm/nordic/nrf5340_cpunet.dtsi:287 */
		};

		/* node '/soc/swi@4101b000' defined in zephyr/dts/arm/nordic/nrf5340_cpunet.dtsi:290 */
		swi1: swi@4101b000 {
			compatible = "nordic,nrf-swi"; /* in zephyr/dts/arm/nordic/nrf5340_cpunet.dtsi:291 */
			reg = < 0x4101b000 0x1000 >;   /* in zephyr/dts/arm/nordic/nrf5340_cpunet.dtsi:292 */
			interrupts = < 0x1b 0x1 >;     /* in zephyr/dts/arm/nordic/nrf5340_cpunet.dtsi:293 */
			status = "okay";               /* in zephyr/dts/arm/nordic/nrf5340_cpunet.dtsi:294 */
		};

		/* node '/soc/swi@4101c000' defined in zephyr/dts/arm/nordic/nrf5340_cpunet.dtsi:297 */
		swi2: swi@4101c000 {
			compatible = "nordic,nrf-swi"; /* in zephyr/dts/arm/nordic/nrf5340_cpunet.dtsi:298 */
			reg = < 0x4101c000 0x1000 >;   /* in zephyr/dts/arm/nordic/nrf5340_cpunet.dtsi:299 */
			interrupts = < 0x1c 0x1 >;     /* in zephyr/dts/arm/nordic/nrf5340_cpunet.dtsi:300 */
			status = "okay";               /* in zephyr/dts/arm/nordic/nrf5340_cpunet.dtsi:301 */
		};

		/* node '/soc/swi@4101d000' defined in zephyr/dts/arm/nordic/nrf5340_cpunet.dtsi:304 */
		swi3: swi@4101d000 {
			compatible = "nordic,nrf-swi"; /* in zephyr/dts/arm/nordic/nrf5340_cpunet.dtsi:305 */
			reg = < 0x4101d000 0x1000 >;   /* in zephyr/dts/arm/nordic/nrf5340_cpunet.dtsi:306 */
			interrupts = < 0x1d 0x1 >;     /* in zephyr/dts/arm/nordic/nrf5340_cpunet.dtsi:307 */
			status = "okay";               /* in zephyr/dts/arm/nordic/nrf5340_cpunet.dtsi:308 */
		};

		/* node '/soc/acl@41080000' defined in zephyr/dts/arm/nordic/nrf5340_cpunet.dtsi:311 */
		acl: acl@41080000 {
			compatible = "nordic,nrf-acl"; /* in zephyr/dts/arm/nordic/nrf5340_cpunet.dtsi:312 */
			reg = < 0x41080000 0x1000 >;   /* in zephyr/dts/arm/nordic/nrf5340_cpunet.dtsi:313 */
			status = "okay";               /* in zephyr/dts/arm/nordic/nrf5340_cpunet.dtsi:314 */
		};

		/* node '/soc/flash-controller@41080000' defined in zephyr/dts/arm/nordic/nrf5340_cpunet.dtsi:317 */
		flash_controller: flash-controller@41080000 {
			compatible = "nordic,nrf53-flash-controller"; /* in zephyr/dts/arm/nordic/nrf5340_cpunet.dtsi:318 */
			reg = < 0x41080000 0x1000 >;                  /* in zephyr/dts/arm/nordic/nrf5340_cpunet.dtsi:319 */
			ranges;                                       /* in zephyr/dts/arm/nordic/nrf5340_cpunet.dtsi:320 */
			partial-erase;                                /* in zephyr/dts/arm/nordic/nrf5340_cpunet.dtsi:321 */
			#address-cells = < 0x1 >;                     /* in zephyr/dts/arm/nordic/nrf5340_cpunet.dtsi:322 */
			#size-cells = < 0x1 >;                        /* in zephyr/dts/arm/nordic/nrf5340_cpunet.dtsi:323 */

			/* node '/soc/flash-controller@41080000/flash@1000000' defined in zephyr/dts/arm/nordic/nrf5340_cpunet.dtsi:325 */
			flash1: flash@1000000 {
				compatible = "soc-nv-flash";        /* in zephyr/dts/arm/nordic/nrf5340_cpunet.dtsi:326 */
				erase-block-size = < 0x800 >;       /* in zephyr/dts/arm/nordic/nrf5340_cpunet.dtsi:327 */
				write-block-size = < 0x4 >;         /* in zephyr/dts/arm/nordic/nrf5340_cpunet.dtsi:328 */
				reg = < 0x1000000 0x40000 >;        /* in zephyr/dts/arm/nordic/nrf5340_cpunet.dtsi:329 */
				ranges = < 0x0 0x1000000 0x40000 >; /* in zephyr/dts/arm/nordic/nrf5340_cpunet.dtsi:330 */
				status = "okay";                    /* in zephyr/dts/arm/nordic/nrf5340_cpunet.dtsi:331 */
				#address-cells = < 0x1 >;           /* in zephyr/dts/arm/nordic/nrf5340_cpunet.dtsi:332 */
				#size-cells = < 0x1 >;              /* in zephyr/dts/arm/nordic/nrf5340_cpunet.dtsi:333 */

				/* node '/soc/flash-controller@41080000/flash@1000000/partitions' defined in zephyr/boards/nordic/nrf5340dk/nrf5340dk_nrf5340_cpunet.dts:79 */
				partitions {
					#address-cells = < 0x1 >; /* in zephyr/boards/nordic/nrf5340dk/nrf5340dk_nrf5340_cpunet.dts:80 */
					#size-cells = < 0x1 >;    /* in zephyr/boards/nordic/nrf5340dk/nrf5340dk_nrf5340_cpunet.dts:81 */
					ranges;                   /* in zephyr/boards/nordic/nrf5340dk/nrf5340dk_nrf5340_cpunet.dts:82 */

					/* node '/soc/flash-controller@41080000/flash@1000000/partitions/partition@0' defined in zephyr/boards/nordic/nrf5340dk/nrf5340dk_nrf5340_cpunet.dts:84 */
					boot_partition: partition@0 {
						compatible = "zephyr,mapped-partition"; /* in zephyr/boards/nordic/nrf5340dk/nrf5340dk_nrf5340_cpunet.dts:85 */
						label = "mcuboot";                      /* in zephyr/boards/nordic/nrf5340dk/nrf5340dk_nrf5340_cpunet.dts:86 */
						reg = < 0x0 0xc000 >;                   /* in zephyr/boards/nordic/nrf5340dk/nrf5340dk_nrf5340_cpunet.dts:87 */
					};

					/* node '/soc/flash-controller@41080000/flash@1000000/partitions/partition@c000' defined in zephyr/boards/nordic/nrf5340dk/nrf5340dk_nrf5340_cpunet.dts:90 */
					slot0_partition: partition@c000 {
						compatible = "zephyr,mapped-partition"; /* in zephyr/boards/nordic/nrf5340dk/nrf5340dk_nrf5340_cpunet.dts:91 */
						label = "image-0";                      /* in zephyr/boards/nordic/nrf5340dk/nrf5340dk_nrf5340_cpunet.dts:92 */
						reg = < 0xc000 0x17000 >;               /* in zephyr/boards/nordic/nrf5340dk/nrf5340dk_nrf5340_cpunet.dts:93 */
					};

					/* node '/soc/flash-controller@41080000/flash@1000000/partitions/partition@23000' defined in zephyr/boards/nordic/nrf5340dk/nrf5340dk_nrf5340_cpunet.dts:96 */
					slot1_partition: partition@23000 {
						compatible = "zephyr,mapped-partition"; /* in zephyr/boards/nordic/nrf5340dk/nrf5340dk_nrf5340_cpunet.dts:97 */
						label = "image-1";                      /* in zephyr/boards/nordic/nrf5340dk/nrf5340dk_nrf5340_cpunet.dts:98 */
						reg = < 0x23000 0x17000 >;              /* in zephyr/boards/nordic/nrf5340dk/nrf5340dk_nrf5340_cpunet.dts:99 */
					};

					/* node '/soc/flash-controller@41080000/flash@1000000/partitions/partition@3a000' defined in zephyr/boards/nordic/nrf5340dk/nrf5340dk_nrf5340_cpunet.dts:102 */
					storage_partition: partition@3a000 {
						compatible = "zephyr,mapped-partition"; /* in zephyr/boards/nordic/nrf5340dk/nrf5340dk_nrf5340_cpunet.dts:103 */
						label = "storage";                      /* in zephyr/boards/nordic/nrf5340dk/nrf5340dk_nrf5340_cpunet.dts:104 */
						reg = < 0x3a000 0x6000 >;               /* in zephyr/boards/nordic/nrf5340dk/nrf5340dk_nrf5340_cpunet.dts:105 */
					};
				};
			};
		};

		/* node '/soc/vmc@41081000' defined in zephyr/dts/arm/nordic/nrf5340_cpunet.dtsi:337 */
		vmc: vmc@41081000 {
			compatible = "nordic,nrf-vmc"; /* in zephyr/dts/arm/nordic/nrf5340_cpunet.dtsi:338 */
			reg = < 0x41081000 0x1000 >;   /* in zephyr/dts/arm/nordic/nrf5340_cpunet.dtsi:339 */
			status = "okay";               /* in zephyr/dts/arm/nordic/nrf5340_cpunet.dtsi:340 */
		};

		/* node '/soc/gpio@418c0500' defined in zephyr/dts/arm/nordic/nrf5340_cpunet.dtsi:343 */
		gpio0: gpio@418c0500 {
			compatible = "nordic,nrf-gpio"; /* in zephyr/dts/arm/nordic/nrf5340_cpunet.dtsi:344 */
			gpio-controller;                /* in zephyr/dts/arm/nordic/nrf5340_cpunet.dtsi:345 */
			reg = < 0x418c0500 0x300 >;     /* in zephyr/dts/arm/nordic/nrf5340_cpunet.dtsi:346 */
			#gpio-cells = < 0x2 >;          /* in zephyr/dts/arm/nordic/nrf5340_cpunet.dtsi:347 */
			port = < 0x0 >;                 /* in zephyr/dts/arm/nordic/nrf5340_cpunet.dtsi:349 */
			gpiote-instance = < &gpiote >;  /* in zephyr/dts/arm/nordic/nrf5340_cpunet.dtsi:350 */
			status = "okay";                /* in zephyr/boards/nordic/nrf5340dk/nrf5340dk_nrf5340_cpunet.dts:42 */
			phandle = < 0xd >;              /* in zephyr/boards/nordic/nrf5340dk/nrf5340dk_common.dtsi:14 */
		};

		/* node '/soc/gpio@418c0800' defined in zephyr/dts/arm/nordic/nrf5340_cpunet.dtsi:353 */
		gpio1: gpio@418c0800 {
			compatible = "nordic,nrf-gpio"; /* in zephyr/dts/arm/nordic/nrf5340_cpunet.dtsi:354 */
			gpio-controller;                /* in zephyr/dts/arm/nordic/nrf5340_cpunet.dtsi:355 */
			reg = < 0x418c0800 0x300 >;     /* in zephyr/dts/arm/nordic/nrf5340_cpunet.dtsi:356 */
			#gpio-cells = < 0x2 >;          /* in zephyr/dts/arm/nordic/nrf5340_cpunet.dtsi:357 */
			ngpios = < 0x10 >;              /* in zephyr/dts/arm/nordic/nrf5340_cpunet.dtsi:358 */
			port = < 0x1 >;                 /* in zephyr/dts/arm/nordic/nrf5340_cpunet.dtsi:360 */
			gpiote-instance = < &gpiote >;  /* in zephyr/dts/arm/nordic/nrf5340_cpunet.dtsi:361 */
			status = "okay";                /* in zephyr/boards/nordic/nrf5340dk/nrf5340dk_nrf5340_cpunet.dts:46 */
			phandle = < 0xe >;              /* in zephyr/boards/nordic/nrf5340dk/nrf5340dk_common.dtsi:67 */
		};
	};

	/* node '/pin-controller' defined in zephyr/dts/vendor/nordic/nrf_common.dtsi:26 */
	pinctrl: pin-controller {
		compatible = "nordic,nrf-pinctrl"; /* in zephyr/dts/vendor/nordic/nrf_common.dtsi:31 */

		/* node '/pin-controller/uart0_default' defined in zephyr/boards/nordic/nrf5340dk/nrf5340dk_nrf5340_cpunet-pinctrl.dtsi:7 */
		uart0_default: uart0_default {
			phandle = < 0x7 >; /* in zephyr/boards/nordic/nrf5340dk/nrf5340dk_nrf5340_cpunet.dts:52 */

			/* node '/pin-controller/uart0_default/group1' defined in zephyr/boards/nordic/nrf5340dk/nrf5340dk_nrf5340_cpunet-pinctrl.dtsi:8 */
			group1 {
				psels = < 0x21 >,
				        < 0x200000b >; /* in zephyr/boards/nordic/nrf5340dk/nrf5340dk_nrf5340_cpunet-pinctrl.dtsi:9 */
			};

			/* node '/pin-controller/uart0_default/group2' defined in zephyr/boards/nordic/nrf5340dk/nrf5340dk_nrf5340_cpunet-pinctrl.dtsi:13 */
			group2 {
				psels = < 0x1000020 >,
				        < 0x300000a >; /* in zephyr/boards/nordic/nrf5340dk/nrf5340dk_nrf5340_cpunet-pinctrl.dtsi:14 */
				bias-pull-up;          /* in zephyr/boards/nordic/nrf5340dk/nrf5340dk_nrf5340_cpunet-pinctrl.dtsi:16 */
			};
		};

		/* node '/pin-controller/uart0_sleep' defined in zephyr/boards/nordic/nrf5340dk/nrf5340dk_nrf5340_cpunet-pinctrl.dtsi:20 */
		uart0_sleep: uart0_sleep {
			phandle = < 0x8 >; /* in zephyr/boards/nordic/nrf5340dk/nrf5340dk_nrf5340_cpunet.dts:53 */

			/* node '/pin-controller/uart0_sleep/group1' defined in zephyr/boards/nordic/nrf5340dk/nrf5340dk_nrf5340_cpunet-pinctrl.dtsi:21 */
			group1 {
				psels = < 0x1000020 >,
				        < 0x200000b >,
				        < 0x300000a >; /* in zephyr/boards/nordic/nrf5340dk/nrf5340dk_nrf5340_cpunet-pinctrl.dtsi:22 */
				low-power-enable;      /* in zephyr/boards/nordic/nrf5340dk/nrf5340dk_nrf5340_cpunet-pinctrl.dtsi:25 */
			};

			/* node '/pin-controller/uart0_sleep/group2' defined in zephyr/boards/nordic/nrf5340dk/nrf5340dk_nrf5340_cpunet-pinctrl.dtsi:28 */
			group2 {
				psels = < 0x21 >; /* in zephyr/boards/nordic/nrf5340dk/nrf5340dk_nrf5340_cpunet-pinctrl.dtsi:29 */
				low-power-enable; /* in zephyr/boards/nordic/nrf5340dk/nrf5340dk_nrf5340_cpunet-pinctrl.dtsi:30 */
				bias-pull-up;     /* in zephyr/boards/nordic/nrf5340dk/nrf5340dk_nrf5340_cpunet-pinctrl.dtsi:31 */
			};
		};

		/* node '/pin-controller/i2c0_default' defined in zephyr/boards/nordic/nrf5340dk/nrf5340dk_nrf5340_cpunet-pinctrl.dtsi:35 */
		i2c0_default: i2c0_default {
			phandle = < 0x2 >; /* in zephyr/boards/nordic/nrf5340dk/nrf5340dk_nrf5340_cpunet.dts:63 */

			/* node '/pin-controller/i2c0_default/group1' defined in zephyr/boards/nordic/nrf5340dk/nrf5340dk_nrf5340_cpunet-pinctrl.dtsi:36 */
			group1 {
				psels = < 0xc000022 >,
				        < 0xb000023 >; /* in zephyr/boards/nordic/nrf5340dk/nrf5340dk_nrf5340_cpunet-pinctrl.dtsi:37 */
			};
		};

		/* node '/pin-controller/i2c0_sleep' defined in zephyr/boards/nordic/nrf5340dk/nrf5340dk_nrf5340_cpunet-pinctrl.dtsi:42 */
		i2c0_sleep: i2c0_sleep {
			phandle = < 0x3 >; /* in zephyr/boards/nordic/nrf5340dk/nrf5340dk_nrf5340_cpunet.dts:64 */

			/* node '/pin-controller/i2c0_sleep/group1' defined in zephyr/boards/nordic/nrf5340dk/nrf5340dk_nrf5340_cpunet-pinctrl.dtsi:43 */
			group1 {
				psels = < 0xc000022 >,
				        < 0xb000023 >; /* in zephyr/boards/nordic/nrf5340dk/nrf5340dk_nrf5340_cpunet-pinctrl.dtsi:44 */
				low-power-enable;      /* in zephyr/boards/nordic/nrf5340dk/nrf5340dk_nrf5340_cpunet-pinctrl.dtsi:46 */
			};
		};

		/* node '/pin-controller/spi0_default' defined in zephyr/boards/nordic/nrf5340dk/nrf5340dk_nrf5340_cpunet-pinctrl.dtsi:50 */
		spi0_default: spi0_default {
			phandle = < 0x5 >; /* in zephyr/boards/nordic/nrf5340dk/nrf5340dk_nrf5340_cpunet.dts:73 */

			/* node '/pin-controller/spi0_default/group1' defined in zephyr/boards/nordic/nrf5340dk/nrf5340dk_nrf5340_cpunet-pinctrl.dtsi:51 */
			group1 {
				psels = < 0x400002f >,
				        < 0x600002e >,
				        < 0x500002d >; /* in zephyr/boards/nordic/nrf5340dk/nrf5340dk_nrf5340_cpunet-pinctrl.dtsi:52 */
			};
		};

		/* node '/pin-controller/spi0_sleep' defined in zephyr/boards/nordic/nrf5340dk/nrf5340dk_nrf5340_cpunet-pinctrl.dtsi:58 */
		spi0_sleep: spi0_sleep {
			phandle = < 0x6 >; /* in zephyr/boards/nordic/nrf5340dk/nrf5340dk_nrf5340_cpunet.dts:74 */

			/* node '/pin-controller/spi0_sleep/group1' defined in zephyr/boards/nordic/nrf5340dk/nrf5340dk_nrf5340_cpunet-pinctrl.dtsi:59 */
			group1 {
				psels = < 0x400002f >,
				        < 0x600002e >,
				        < 0x500002d >; /* in zephyr/boards/nordic/nrf5340dk/nrf5340dk_nrf5340_cpunet-pinctrl.dtsi:60 */
				low-power-enable;      /* in zephyr/boards/nordic/nrf5340dk/nrf5340dk_nrf5340_cpunet-pinctrl.dtsi:63 */
			};
		};
	};

	/* node '/entropy_bt_hci' defined in zephyr/dts/vendor/nordic/nrf_common.dtsi:34 */
	rng_hci: entropy_bt_hci {
		compatible = "zephyr,bt-hci-entropy"; /* in zephyr/dts/vendor/nordic/nrf_common.dtsi:35 */
		status = "disabled";                  /* in zephyr/dts/vendor/nordic/nrf_common.dtsi:36 */
	};

	/* node '/sw-pwm' defined in zephyr/dts/vendor/nordic/nrf_common.dtsi:39 */
	sw_pwm: sw-pwm {
		compatible = "nordic,nrf-sw-pwm"; /* in zephyr/dts/vendor/nordic/nrf_common.dtsi:40 */
		status = "disabled";              /* in zephyr/dts/vendor/nordic/nrf_common.dtsi:41 */
		generator = < &timer1 >;          /* in zephyr/dts/vendor/nordic/nrf_common.dtsi:42 */
		clock-prescaler = < 0x0 >;        /* in zephyr/dts/vendor/nordic/nrf_common.dtsi:43 */
		#pwm-cells = < 0x3 >;             /* in zephyr/dts/vendor/nordic/nrf_common.dtsi:44 */
	};

	/* node '/clocks' defined in zephyr/dts/arm/nordic/nrf5340_clocks.dtsi:8 */
	clocks {

		/* node '/clocks/lfxo' defined in zephyr/dts/arm/nordic/nrf5340_clocks.dtsi:9 */
		lfxo: lfxo {
			compatible = "nordic,nrf53-lfxo"; /* in zephyr/dts/arm/nordic/nrf5340_clocks.dtsi:10 */
			#clock-cells = < 0x0 >;           /* in zephyr/dts/arm/nordic/nrf5340_clocks.dtsi:11 */
			clock-frequency = < 0x8000 >;     /* in zephyr/dts/arm/nordic/nrf5340_clocks.dtsi:12 */
		};

		/* node '/clocks/hfxo' defined in zephyr/dts/arm/nordic/nrf5340_clocks.dtsi:15 */
		hfxo: hfxo {
			compatible = "nordic,nrf53-hfxo"; /* in zephyr/dts/arm/nordic/nrf5340_clocks.dtsi:16 */
			#clock-cells = < 0x0 >;           /* in zephyr/dts/arm/nordic/nrf5340_clocks.dtsi:17 */
			clock-frequency = < 0x1e84800 >;  /* in zephyr/dts/arm/nordic/nrf5340_clocks.dtsi:18 */
			startup-time-us = < 0x578 >;      /* in zephyr/dts/arm/nordic/nrf5340_clocks.dtsi:19 */
		};
	};

	/* node '/cpus' defined in zephyr/dts/arm/nordic/nrf5340_cpunet.dtsi:18 */
	cpus {
		#address-cells = < 0x1 >; /* in zephyr/dts/arm/nordic/nrf5340_cpunet.dtsi:19 */
		#size-cells = < 0x0 >;    /* in zephyr/dts/arm/nordic/nrf5340_cpunet.dtsi:20 */

		/* node '/cpus/cpu@1' defined in zephyr/dts/arm/nordic/nrf5340_cpunet.dtsi:22 */
		cpu@1 {
			device_type = "cpu";           /* in zephyr/dts/arm/nordic/nrf5340_cpunet.dtsi:23 */
			compatible = "arm,cortex-m33"; /* in zephyr/dts/arm/nordic/nrf5340_cpunet.dtsi:24 */
			reg = < 0x1 >;                 /* in zephyr/dts/arm/nordic/nrf5340_cpunet.dtsi:25 */
			#address-cells = < 0x1 >;      /* in zephyr/dts/arm/nordic/nrf5340_cpunet.dtsi:26 */
			#size-cells = < 0x1 >;         /* in zephyr/dts/arm/nordic/nrf5340_cpunet.dtsi:27 */

			/* node '/cpus/cpu@1/mpu@e000ed90' defined in zephyr/dts/arm/nordic/nrf5340_cpunet.dtsi:29 */
			mpu: mpu@e000ed90 {
				compatible = "arm,armv8m-mpu"; /* in zephyr/dts/arm/nordic/nrf5340_cpunet.dtsi:30 */
				reg = < 0xe000ed90 0x40 >;     /* in zephyr/dts/arm/nordic/nrf5340_cpunet.dtsi:31 */
			};
		};
	};

	/* node '/ipc' defined in zephyr/dts/arm/nordic/nrf5340_cpunet.dtsi:366 */
	ipc {

		/* node '/ipc/ipc0' defined in zephyr/dts/arm/nordic/nrf5340_cpunet.dtsi:367 */
		ipc0: ipc0 {
			compatible = "zephyr,ipc-openamp-static-vrings"; /* in zephyr/dts/arm/nordic/nrf5340_cpunet.dtsi:368 */
			memory-region = < &sram0_shared >;               /* in zephyr/dts/arm/nordic/nrf5340_cpunet.dtsi:369 */
			mboxes = < &mbox 0x0 >,
			         < &mbox 0x1 >;                          /* in zephyr/dts/arm/nordic/nrf5340_cpunet.dtsi:370 */
			mbox-names = "rx",
			             "tx";                               /* in zephyr/dts/arm/nordic/nrf5340_cpunet.dtsi:371 */
			role = "remote";                                 /* in zephyr/dts/arm/nordic/nrf5340_cpunet.dtsi:372 */
			status = "okay";                                 /* in zephyr/dts/arm/nordic/nrf5340_cpunet.dtsi:373 */
		};
	};

	/* node '/leds' defined in zephyr/boards/nordic/nrf5340dk/nrf5340dk_common.dtsi:10 */
	leds {
		compatible = "gpio-leds"; /* in zephyr/boards/nordic/nrf5340dk/nrf5340dk_common.dtsi:11 */

		/* node '/leds/led_0' defined in zephyr/boards/nordic/nrf5340dk/nrf5340dk_common.dtsi:13 */
		led0: led_0 {
			gpios = < &gpio0 0x1c 0x1 >; /* in zephyr/boards/nordic/nrf5340dk/nrf5340dk_common.dtsi:14 */
			label = "Green LED 0";       /* in zephyr/boards/nordic/nrf5340dk/nrf5340dk_common.dtsi:15 */
		};

		/* node '/leds/led_1' defined in zephyr/boards/nordic/nrf5340dk/nrf5340dk_common.dtsi:18 */
		led1: led_1 {
			gpios = < &gpio0 0x1d 0x1 >; /* in zephyr/boards/nordic/nrf5340dk/nrf5340dk_common.dtsi:19 */
			label = "Green LED 1";       /* in zephyr/boards/nordic/nrf5340dk/nrf5340dk_common.dtsi:20 */
		};

		/* node '/leds/led_2' defined in zephyr/boards/nordic/nrf5340dk/nrf5340dk_common.dtsi:23 */
		led2: led_2 {
			gpios = < &gpio0 0x1e 0x1 >; /* in zephyr/boards/nordic/nrf5340dk/nrf5340dk_common.dtsi:24 */
			label = "Green LED 2";       /* in zephyr/boards/nordic/nrf5340dk/nrf5340dk_common.dtsi:25 */
		};

		/* node '/leds/led_3' defined in zephyr/boards/nordic/nrf5340dk/nrf5340dk_common.dtsi:28 */
		led3: led_3 {
			gpios = < &gpio0 0x1f 0x1 >; /* in zephyr/boards/nordic/nrf5340dk/nrf5340dk_common.dtsi:29 */
			label = "Green LED 3";       /* in zephyr/boards/nordic/nrf5340dk/nrf5340dk_common.dtsi:30 */
		};
	};

	/* node '/buttons' defined in zephyr/boards/nordic/nrf5340dk/nrf5340dk_common.dtsi:34 */
	buttons {
		compatible = "gpio-keys"; /* in zephyr/boards/nordic/nrf5340dk/nrf5340dk_common.dtsi:35 */

		/* node '/buttons/button_0' defined in zephyr/boards/nordic/nrf5340dk/nrf5340dk_common.dtsi:37 */
		button0: button_0 {
			gpios = < &gpio0 0x17 0x11 >; /* in zephyr/boards/nordic/nrf5340dk/nrf5340dk_common.dtsi:38 */
			label = "Push button 1";      /* in zephyr/boards/nordic/nrf5340dk/nrf5340dk_common.dtsi:39 */
			zephyr,code = < 0xb >;        /* in zephyr/boards/nordic/nrf5340dk/nrf5340dk_common.dtsi:40 */
		};

		/* node '/buttons/button_1' defined in zephyr/boards/nordic/nrf5340dk/nrf5340dk_common.dtsi:43 */
		button1: button_1 {
			gpios = < &gpio0 0x18 0x11 >; /* in zephyr/boards/nordic/nrf5340dk/nrf5340dk_common.dtsi:44 */
			label = "Push button 2";      /* in zephyr/boards/nordic/nrf5340dk/nrf5340dk_common.dtsi:45 */
			zephyr,code = < 0x2 >;        /* in zephyr/boards/nordic/nrf5340dk/nrf5340dk_common.dtsi:46 */
		};

		/* node '/buttons/button_2' defined in zephyr/boards/nordic/nrf5340dk/nrf5340dk_common.dtsi:49 */
		button2: button_2 {
			gpios = < &gpio0 0x8 0x11 >; /* in zephyr/boards/nordic/nrf5340dk/nrf5340dk_common.dtsi:50 */
			label = "Push button 3";     /* in zephyr/boards/nordic/nrf5340dk/nrf5340dk_common.dtsi:51 */
			zephyr,code = < 0x3 >;       /* in zephyr/boards/nordic/nrf5340dk/nrf5340dk_common.dtsi:52 */
		};

		/* node '/buttons/button_3' defined in zephyr/boards/nordic/nrf5340dk/nrf5340dk_common.dtsi:55 */
		button3: button_3 {
			gpios = < &gpio0 0x9 0x11 >; /* in zephyr/boards/nordic/nrf5340dk/nrf5340dk_common.dtsi:56 */
			label = "Push button 4";     /* in zephyr/boards/nordic/nrf5340dk/nrf5340dk_common.dtsi:57 */
			zephyr,code = < 0x4 >;       /* in zephyr/boards/nordic/nrf5340dk/nrf5340dk_common.dtsi:58 */
		};
	};

	/* node '/connector' defined in zephyr/boards/nordic/nrf5340dk/nrf5340dk_common.dtsi:62 */
	arduino_header: connector {
		compatible = "arduino-header-r3";          /* in zephyr/boards/nordic/nrf5340dk/nrf5340dk_common.dtsi:63 */
		#gpio-cells = < 0x2 >;                     /* in zephyr/boards/nordic/nrf5340dk/nrf5340dk_common.dtsi:64 */
		gpio-map-mask = < 0xffffffff 0xffffffc0 >; /* in zephyr/boards/nordic/nrf5340dk/nrf5340dk_common.dtsi:65 */
		gpio-map-pass-thru = < 0x0 0x3f >;         /* in zephyr/boards/nordic/nrf5340dk/nrf5340dk_common.dtsi:66 */
		gpio-map = < 0x0 0x0 &gpio0 0x4 0x0 >,
		           < 0x1 0x0 &gpio0 0x5 0x0 >,
		           < 0x2 0x0 &gpio0 0x6 0x0 >,
		           < 0x3 0x0 &gpio0 0x7 0x0 >,
		           < 0x4 0x0 &gpio0 0x19 0x0 >,
		           < 0x5 0x0 &gpio0 0x1a 0x0 >,
		           < 0x6 0x0 &gpio1 0x0 0x0 >,
		           < 0x7 0x0 &gpio1 0x1 0x0 >,
		           < 0x8 0x0 &gpio1 0x4 0x0 >,
		           < 0x9 0x0 &gpio1 0x5 0x0 >,
		           < 0xa 0x0 &gpio1 0x6 0x0 >,
		           < 0xb 0x0 &gpio1 0x7 0x0 >,
		           < 0xc 0x0 &gpio1 0x8 0x0 >,
		           < 0xd 0x0 &gpio1 0x9 0x0 >,
		           < 0xe 0x0 &gpio1 0xa 0x0 >,
		           < 0xf 0x0 &gpio1 0xb 0x0 >,
		           < 0x10 0x0 &gpio1 0xc 0x0 >,
		           < 0x11 0x0 &gpio1 0xd 0x0 >,
		           < 0x12 0x0 &gpio1 0xe 0x0 >,
		           < 0x13 0x0 &gpio1 0xf 0x0 >,
		           < 0x14 0x0 &gpio1 0x2 0x0 >,
		           < 0x15 0x0 &gpio1 0x3 0x0 >;    /* in zephyr/boards/nordic/nrf5340dk/nrf5340dk_common.dtsi:67 */
		phandle = < 0x4 >;                         /* in zephyr/boards/nordic/nrf5340dk/nrf5340dk_nrf5340_cpunet.dts:72 */
	};
};
